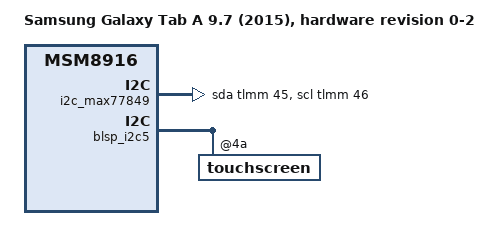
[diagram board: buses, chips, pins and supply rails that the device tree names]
// SPDX-License-Identifier: GPL-2.0-only

/* Samsung downstream revisions 0 through 2 route MAX77849 on GPIO45/46. */
#include "msm8916-samsung-gt510.dts"

/ {
	model = "Samsung Galaxy Tab A 9.7 (2015), hardware revision 0-2";
};

&i2c_max77849 {
	sda-gpios = <&tlmm 45 (GPIO_ACTIVE_HIGH | GPIO_OPEN_DRAIN)>;
	scl-gpios = <&tlmm 46 (GPIO_ACTIVE_HIGH | GPIO_OPEN_DRAIN)>;
};

&blsp_i2c5 {
	touchscreen@4a {
		/* Downstream revisions 0-2 report keys on T15 bits 1 and 2. */
		linux,keycodes = <KEY_RESERVED KEY_APPSELECT KEY_BACK>;
	};
};

&max77849_i2c_default {
	pins = "gpio45", "gpio46";
};
